# STM32H5F5 register map
File version: 1.0
CPU: CM33 r0p0, little endian, MPU, FPU, 4 interrupt priority bits
Registers are 32-bit, read-write, reset 0x0 unless marked. A register's access mark holds for its fields unless they carry their own. Offsets are from the block's base; [hi:lo] are bit positions; lines under a group give offsets from that group; {n}, {i} and the like mark numbered series.

## ADC — ADC register block
Base 0x42028000
Same registers: ADC3 0x4202D800, ADC_S 0x52028000, ADC3_S 0x5202D800
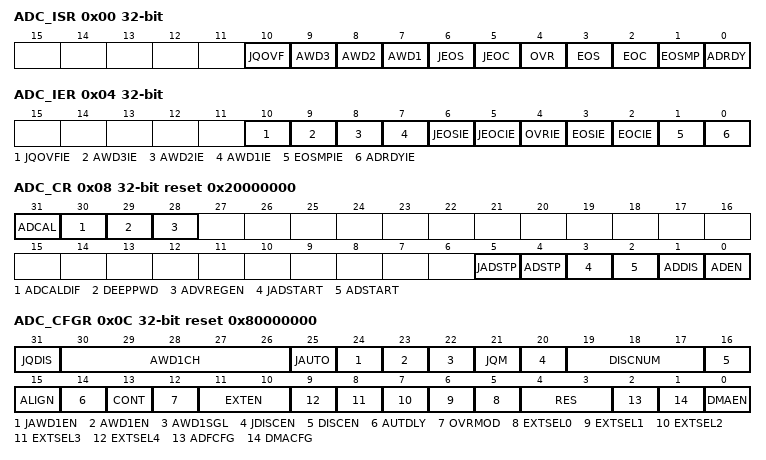
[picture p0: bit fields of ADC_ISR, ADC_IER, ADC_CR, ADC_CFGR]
0x00 ADC_ISR — ADC interrupt and status register
  [10] JQOVF — Injected context queue overflow
    0=No injected context queue overflow occurred (or the flag event was already acknowledged and cleared by software); 1=Injected context queue overflow has occurred
  [9] AWD3 — Analog watchdog 3 flag
    0=No analog watchdog 3 event occurred (or the flag event was already acknowledged and cleared by software); 1=Analog watchdog 3 event occurred
  [8] AWD2 — Analog watchdog 2 flag
    0=No analog watchdog 2 event occurred (or the flag event was already acknowledged and cleared by software); 1=Analog watchdog 2 event occurred
  [7] AWD1 — Analog watchdog 1 flag
    0=No analog watchdog 1 event occurred (or the flag event was already acknowledged and cleared by software); 1=Analog watchdog 1 event occurred
  [6] JEOS — Injected channel end of sequence flag
    0=Injected conversion sequence not complete (or the flag event was already acknowledged and cleared by software); 1=Injected conversions complete
  [5] JEOC — Injected channel end of conversion flag
    0=Injected channel conversion not complete (or the flag event was already acknowledged and cleared by software); 1=Injected channel conversion complete
  [4] OVR — ADC overrun
    0=No overrun occurred (or the flag event was already acknowledged and cleared by software); 1=Overrun has occurred
  [3] EOS — End of regular sequence flag
    0=Regular Conversions sequence not complete (or the flag event was already acknowledged and cleared by software); 1=Regular Conversions sequence complete
  [2] EOC — End of conversion flag
    0=Regular channel conversion not complete (or the flag event was already acknowledged and cleared by software); 1=Regular channel conversion complete
  [1] EOSMP — End of sampling flag
    0=not at the end of the sampling phase (or the flag event was already acknowledged and cleared by software); 1=End of sampling phase reached
  [0] ADRDY — ADC ready
    0=ADC not yet ready to start conversion (or the flag event was already acknowledged and cleared by software); 1=ADC is ready to start conversion
0x04 ADC_IER — ADC interrupt enable register
  [10] JQOVFIE — Injected context queue overflow interrupt enable
    0=Injected Context Queue Overflow interrupt disabled; 1=Injected Context Queue Overflow interrupt enabled
  [9] AWD3IE — Analog watchdog 3 interrupt enable
    0=Analog watchdog 3 interrupt disabled; 1=Analog watchdog 3 interrupt enabled
  [8] AWD2IE — Analog watchdog 2 interrupt enable
    0=Analog watchdog 2 interrupt disabled; 1=Analog watchdog 2 interrupt enabled
  [7] AWD1IE — Analog watchdog 1 interrupt enable
    0=Analog watchdog 1 interrupt disabled; 1=Analog watchdog 1 interrupt enabled
  [6] JEOSIE — End of injected sequence of conversions interrupt enable
    0=JEOS interrupt disabled; 1=JEOS interrupt enabled
  [5] JEOCIE — End of injected conversion interrupt enable
    0=JEOC interrupt disabled; 1=JEOC interrupt enabled
  [4] OVRIE — Overrun interrupt enable
    0=Overrun interrupt disabled; 1=Overrun interrupt enabled
  [3] EOSIE — End of regular sequence of conversions interrupt enable
    0=EOS interrupt disabled; 1=EOS interrupt enabled
  [2] EOCIE — End of regular conversion interrupt enable
    0=EOC interrupt disabled; 1=EOC interrupt enabled
  [1] EOSMPIE — End of sampling flag interrupt enable for regular conversions
    0=EOSMP interrupt disabled; 1=EOSMP interrupt enabled
  [0] ADRDYIE — ADC ready interrupt enable
    0=ADRDY interrupt disabled; 1=ADRDY interrupt enabled
0x08 ADC_CR reset 0x20000000 — ADC control register
  [31] ADCAL — ADC calibration
    0=Calibration complete; 1=Write 1 to calibrate the ADC
  [30] ADCALDIF — Differential mode for calibration
    0=Writing ADCAL launches a calibration in single-ended inputs mode; 1=Writing ADCAL launches a calibration in Differential inputs mode
  [29] DEEPPWD — Deep-power-down enable
    0=ADC not in Deep-power down; 1=ADC in Deep-power-down (default reset state)
  [28] ADVREGEN — ADC voltage regulator enable
    0=ADC Voltage regulator disabled; 1=ADC Voltage regulator enabled
  [5] JADSTP — ADC stop of injected conversion command
    0=No ADC stop injected conversion command ongoing; 1=Write 1 to stop injected conversions ongoing
  [4] ADSTP — ADC stop of regular conversion command
    0=No ADC stop regular conversion command ongoing; 1=Write 1 to stop regular conversions ongoing
  [3] JADSTART — ADC start of injected conversion
    0=No ADC injected conversion is ongoing; 1=Write 1 to start injected conversions
  [2] ADSTART — ADC start of regular conversion
    0=No ADC regular conversion is ongoing; 1=Write 1 to start regular conversions
  [1] ADDIS — ADC disable command
    0=no ADDIS command ongoing; 1=Write 1 to disable the ADC
  [0] ADEN — ADC enable control
    0=ADC is disabled (OFF state); 1=Write 1 to enable the ADC
0x0C ADC_CFGR reset 0x80000000 — ADC configuration register
  [31] JQDIS — Injected queue disable
    0=Injected queue enabled; 1=Injected queue disabled
  [30:26] AWD1CH — Analog watchdog 1 channel selection
    0=ADC analog input channel 0 monitored by AWD1 (available on ADC1 only); 1=ADC analog input channel 1 monitored by AWD1; 19=ADC analog input channel 19 monitored by AWD1
  [25] JAUTO — Automatic injected group conversion
    0=Automatic injected group conversion disabled; 1=Automatic injected group conversion enabled
  [24] JAWD1EN — Analog watchdog 1 enable on injected channels
    0=Analog watchdog 1 disabled on injected channels; 1=Analog watchdog 1 enabled on injected channels
  [23] AWD1EN — Analog watchdog 1 enable on regular channels
    0=Analog watchdog 1 disabled on regular channels; 1=Analog watchdog 1 enabled on regular channels
  [22] AWD1SGL — Enable the watchdog 1 on a single channel or on all channels
    0=Analog watchdog 1 enabled on all channels; 1=Analog watchdog 1 enabled on a single channel
  [21] JQM — JSQR queue mode
    0=JSQR mode 0: The Queue is never empty and maintains the last written configuration into JSQR; 1=JSQR mode 1: The Queue can be empty and when this occurs, the software and hardware triggers of the injected sequence are both internally disabled just after the completion of the last valid injected sequence
  [20] JDISCEN — Discontinuous mode on injected channels
    0=Discontinuous mode on injected channels disabled; 1=Discontinuous mode on injected channels enabled
  [19:17] DISCNUM — Discontinuous mode channel count
    0=1 channel; 1=2 channels; 7=8 channels
  [16] DISCEN — Discontinuous mode for regular channels
    0=Discontinuous mode for regular channels disabled; 1=Discontinuous mode for regular channels enabled
  [15] ALIGN — Data alignment
    0=Right alignment; 1=Left alignment
  [14] AUTDLY — Delayed conversion mode
    0=Auto-delayed conversion mode off; 1=Auto-delayed conversion mode on
  [13] CONT — Single / continuous conversion mode for regular conversions
    0=Single conversion mode; 1=Continuous conversion mode
  [12] OVRMOD — Overrun mode
    0=ADC_DR register is preserved with the old data when an overrun is detected; 1=ADC_DR register is overwritten with the last conversion result when an overrun is detected
  [11:10] EXTEN — External trigger enable and polarity selection for regular channels
    0=Hardware trigger detection disabled (conversions can be launched by software); 1=Hardware trigger detection on the rising edge; 2=Hardware trigger detection on the falling edge; 3=Hardware trigger detection on both the rising and falling edges
  [n+5] EXTSEL{n} (n=0..4) — External trigger selection for regular group
    0=adc_ext_trg0; 1=adc_ext_trg1
  [4:3] RES — Data resolution
    0=12-bit; 1=10-bit; 2=8-bit; 3=6-bit
  [2] ADFCFG — ADF mode configuration
    0=ADF mode disabled; 1=ADF mode enabled
  [1] DMACFG — Direct memory access configuration
    0=DMA One Shot mode selected; 1=DMA Circular mode selected
  [0] DMAEN — Direct memory access enable
    0=DMA disabled; 1=DMA enabled
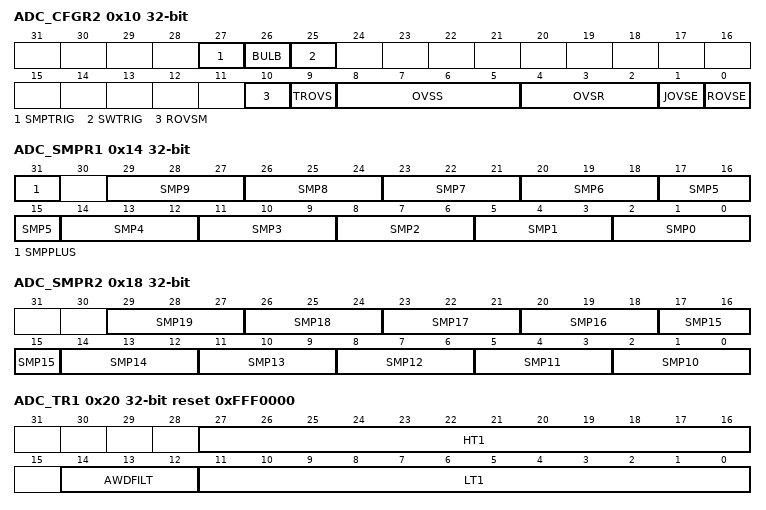
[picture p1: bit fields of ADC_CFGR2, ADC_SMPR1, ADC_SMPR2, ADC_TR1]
0x10 ADC_CFGR2 — ADC configuration register 2
  [27] SMPTRIG — Sampling time control trigger mode
    0=Sampling time control trigger mode disabled; 1=Sampling time control trigger mode enabled
  [26] BULB — Bulb sampling mode
    0=Bulb sampling mode disabled; 1=Bulb sampling mode enabled
  [25] SWTRIG — Software trigger bit for sampling time control trigger mode
    0=Software trigger starts the conversion for sampling time control trigger mode; 1=Software trigger starts the sampling for sampling time control trigger mode
  [10] ROVSM — Regular oversampling mode
    0=Continued mode: When injected conversions are triggered, the oversampling is temporary stopped and continued after the injection sequence (oversampling buffer is maintained during injected sequence); 1=Resumed mode: When injected conversions are triggered, the current oversampling is aborted and resumed from start after the injection sequence (oversampling buffer is zeroed by injected sequence start)
  [9] TROVS — Triggered Regular oversampling
    0=All oversampled conversions for a channel are done consecutively following a trigger; 1=Each oversampled conversion for a channel needs a new trigger
  [8:5] OVSS — Oversampling shift
    0=No shift; 1=Shift 1-bit; {v}=Shift {v}-bits (v=2..8)
  [4:2] OVSR — Oversampling ratio
    0=2x; 1=4x; 2=8x; 3=16x; 4=32x; 5=64x; 6=128x; 7=256x
  [1] JOVSE — Injected oversampling Enable
    0=Injected oversampling disabled; 1=Injected oversampling enabled
  [0] ROVSE — Regular oversampling Enable
    0=Regular oversampling disabled; 1=Regular oversampling enabled
0x14 ADC_SMPR1 — ADC sample time register 1
  [31] SMPPLUS — Addition of one clock cycle to the sampling time.
    1=2; 0=The sampling time remains set to 2
  [3n+2:3n] SMP{n} (n=0..9) — Channel x sampling time selection (x=9 to 0)
    0=2; 1=6; 2=12; 3=24; 4=47; 5=92; 6=247; 7=640
0x18 ADC_SMPR2 — ADC sample time register 2
  [all] fields
    0=2; 1=6; 2=12; 3=24; 4=47; 5=92; 6=247; 7=640
  [3n-28:3n-30] SMP{n} (n=10..19) — Channel x sampling time selection (x=19 to 10)
0x20 ADC_TR1 reset 0xFFF0000 — ADC watchdog threshold register 1
  [27:16] HT1 — Analog watchdog 1 higher threshold
  [14:12] AWDFILT — Analog watchdog filtering parameter
    0=No filtering; 1=two consecutive detection generates an AWDx flag or an interrupt; 7=Eight consecutive detection generates an AWDx flag or an interrupt
  [11:0] LT1 — Analog watchdog 1 lower threshold
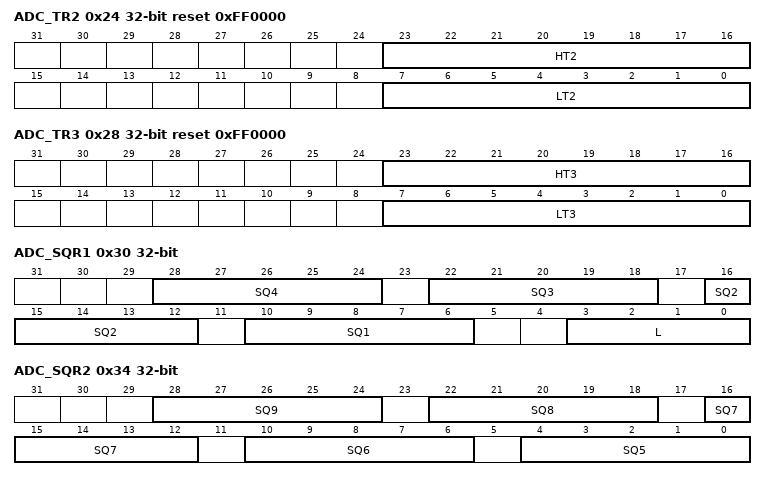
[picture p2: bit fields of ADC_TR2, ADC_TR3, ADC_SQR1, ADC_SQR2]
0x24 ADC_TR2 reset 0xFF0000 — ADC watchdog threshold register 2
  [23:16] HT2 — Analog watchdog 2 higher threshold
  [7:0] LT2 — Analog watchdog 2 lower threshold
0x28 ADC_TR3 reset 0xFF0000 — ADC watchdog threshold register 3
  [23:16] HT3 — Analog watchdog 3 higher threshold
  [7:0] LT3 — Analog watchdog 3 lower threshold
0x30 ADC_SQR1 — ADC regular sequence register 1
  [28:24] SQ4 — 4th conversion in regular sequence
  [22:18] SQ3 — 3rd conversion in regular sequence
  [16:12] SQ2 — 2nd conversion in regular sequence
  [10:6] SQ1 — 1st conversion in regular sequence
  [3:0] L — Regular channel sequence length
    0=1 conversion; 1=2 conversions; 15=16 conversions
0x34 ADC_SQR2 — ADC regular sequence register 2
  [6n-26:6n-30] SQ{n} (n=5..9) — {n}th conversion in regular sequence
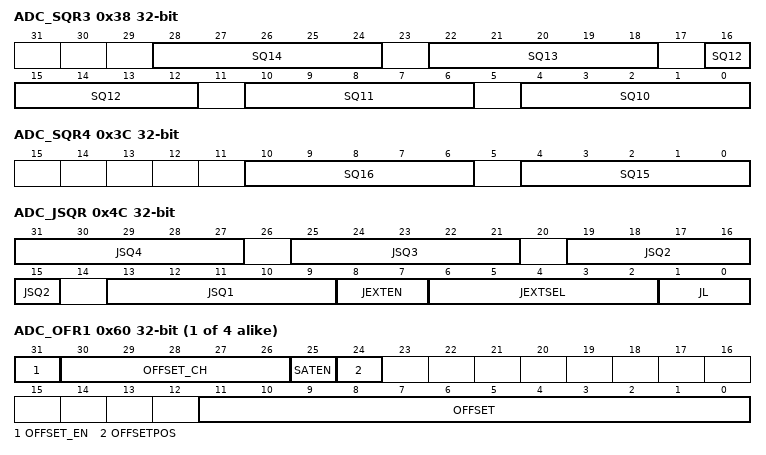
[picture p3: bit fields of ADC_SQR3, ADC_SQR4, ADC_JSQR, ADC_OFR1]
0x38 ADC_SQR3 — ADC regular sequence register 3
  [6n-56:6n-60] SQ{n} (n=10..14) — {n}th conversion in regular sequence
0x3C ADC_SQR4 — ADC regular sequence register 4
  [10:6] SQ16 — 16th conversion in regular sequence
  [4:0] SQ15 — 15th conversion in regular sequence
0x40 ADC_DR ro — ADC regular data register
  [15:0] RDATA — Regular data converted
0x4C ADC_JSQR — ADC injected sequence register
  [31:27] JSQ4 — 4th conversion in the injected sequence
  [25:21] JSQ3 — 3rd conversion in the injected sequence
  [19:15] JSQ2 — 2nd conversion in the injected sequence
  [13:9] JSQ1 — 1st conversion in the injected sequence
  [8:7] JEXTEN — External trigger enable and polarity selection for injected channels
    0=If JQDIS=0 (queue enabled), hardware and software trigger detection disabled; 1=Hardware trigger detection on the rising edge; 2=Hardware trigger detection on the falling edge; 3=Hardware trigger detection on both the rising and falling edges
  [6:2] JEXTSEL — External Trigger Selection for injected group
    {v}=adc_jext_trg{v} (v=0..7); 31=adc_jext_trg31
  [1:0] JL — Injected channel sequence length
    0=1 conversion; 1=2 conversions; 2=3 conversions; 3=4 conversions
{0x5C+4i} ADC_OFR{i} (i=1..4) — ADC offset {i} register
  [31] OFFSET_EN — Offset y enable
  [30:26] OFFSET_CH — Channel selection for the data offset y
  [25] SATEN — Saturation enable
    0=No saturation control, offset result can be signed; 1=Saturation enabled, offset result unsigned and saturated at 0x000 and 0xFFF
  [24] OFFSETPOS — Positive offset
    0=Negative offset; 1=Positive offset
  [11:0] OFFSET — Data offset y for the channel programmed into bits OFFSET_CH[4:0]
{0x7C+4i} ADC_JDR{i} ro (i=1..4) — ADC injected channel {i} data register
  [15:0] JDATA — Injected data
0xA0 ADC_AWD2CR — ADC analog watchdog 2 configuration register
  [19:0] AWD2CH — Analog watchdog 2 channel selection
0xA4 ADC_AWD3CR — ADC analog watchdog 3 configuration register
  [19:0] AWD3CH — Analog watchdog 3 channel selection
0xB0 ADC_DIFSEL — ADC Differential mode selection register
  [19:0] DIFSEL — Differential mode for channels 19 to 0.
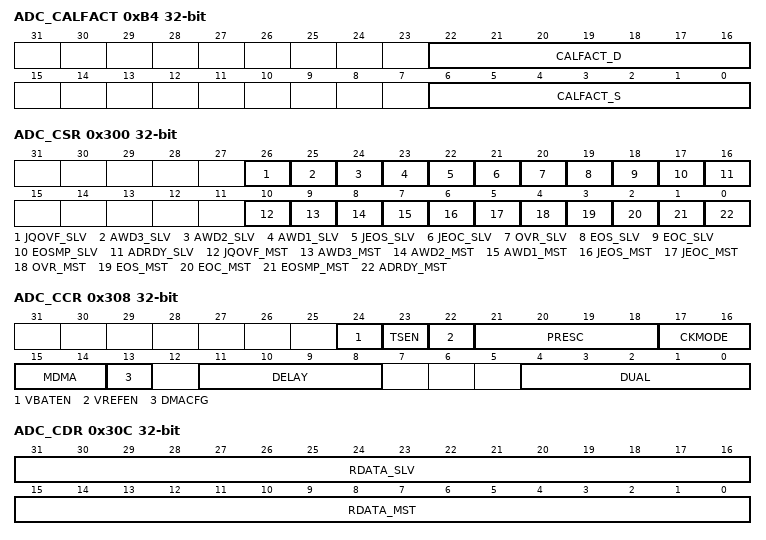
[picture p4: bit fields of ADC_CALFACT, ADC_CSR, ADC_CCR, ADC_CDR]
0xB4 ADC_CALFACT — ADC calibration factors
  [22:16] CALFACT_D — Calibration Factors in differential mode
  [6:0] CALFACT_S — Calibration Factors In single-ended mode
0xC8 ADC_OR — ADC option register
  [0] OP0 — Option bit 0
    0=INP0less thansub> less than/sub>GPIO switch control disabled; 1=INP0less thansub> less than/sub>GPIO switch control enabled
0x300 ADC_CSR ro — ADC common status register
  [26] JQOVF_SLV — Injected Context Queue Overflow flag of the slave ADC
  [25] AWD3_SLV — Analog watchdog 3 flag of the slave ADC
  [24] AWD2_SLV — Analog watchdog 2 flag of the slave ADC
  [23] AWD1_SLV — Analog watchdog 1 flag of the slave ADC
  [22] JEOS_SLV — End of injected sequence flag of the slave ADC
  [21] JEOC_SLV — End of injected conversion flag of the slave ADC
  [20] OVR_SLV — Overrun flag of the slave ADC
  [19] EOS_SLV — End of regular sequence flag of the slave ADC.
  [18] EOC_SLV — End of regular conversion of the slave ADC
  [17] EOSMP_SLV — End of Sampling phase flag of the slave ADC
  [16] ADRDY_SLV — Slave ADC ready
  [10] JQOVF_MST — Injected Context Queue Overflow flag of the master ADC
  [9] AWD3_MST — Analog watchdog 3 flag of the master ADC
  [8] AWD2_MST — Analog watchdog 2 flag of the master ADC
  [7] AWD1_MST — Analog watchdog 1 flag of the master ADC
  [6] JEOS_MST — End of injected sequence flag of the master ADC
  [5] JEOC_MST — End of injected conversion flag of the master ADC
  [4] OVR_MST — Overrun flag of the master ADC
  [3] EOS_MST — End of regular sequence flag of the master ADC
  [2] EOC_MST — End of regular conversion of the master ADC
  [1] EOSMP_MST — End of Sampling phase flag of the master ADC
  [0] ADRDY_MST — Master ADC ready
0x308 ADC_CCR — ADC common control register
  [24] VBATEN — VBAT enable
    0=Vless thansub>BATless than/sub> channel disabled; 1=Vless thansub>BATless than/sub> channel enabled
  [23] TSEN — Vless thansub>SENSEless than/sub> enable
    0=Temperature sensor channel disabled; 1=Temperature sensor channel enabled
  [22] VREFEN — Vless thansub>REFINTless than/sub> enable
    0=Vless thansub>REFINTless than/sub> channel disabled; 1=Vless thansub>REFINTless than/sub> channel enabled
  [21:18] PRESC — ADC prescaler
    0=input ADC clock not divided; 1=input ADC clock divided by 2; 2=input ADC clock divided by 4; 3=input ADC clock divided by 6; 4=input ADC clock divided by 8; 5=input ADC clock divided by 10; 6=input ADC clock divided by 12; 7=input ADC clock divided by 16; 8=input ADC clock divided by 32; 9=input ADC clock divided by 64; 10=input ADC clock divided by 128; 11=input ADC clock divided by 256
  [17:16] CKMODE — ADC clock mode
    0=adc_ker_ck (x = 1/2/3) (Asynchronous clock mode), generated at product level (refer to Section6: Reset and clock control (RCC)); 1=adc_hclk/1 (Synchronous clock mode); 2=adc_hclk/2 (Synchronous clock mode); 3=adc_hclk/4 (Synchronous clock mode)
  [15:14] MDMA — Direct memory access mode for dual ADC mode
    0=MDMA mode disabled; 2=MDMA mode enabled for 12 and 10-bit resolution; 3=MDMA mode enabled for 8 and 6-bit resolution
  [13] DMACFG — DMA configuration (for dual ADC mode)
    0=DMA One Shot mode selected; 1=DMA Circular mode selected
  [11:8] DELAY — Delay between 2 sampling phases
  [4:0] DUAL — Dual ADC mode selection
    0=Independent mode; 1=Combined regular simultaneous + injected simultaneous mode; 2=Combined regular simultaneous + alternate trigger mode; 3=Combined interleaved mode + injected simultaneous mode; 5=Injected simultaneous mode only; 6=Regular simultaneous mode only; 7=Interleaved mode only; 9=Alternate trigger mode only
0x30C ADC_CDR ro — ADC common regular data register for dual mode
  [31:16] RDATA_SLV — Regular data of the slave ADC
  [15:0] RDATA_MST — Regular data of the master ADC.
